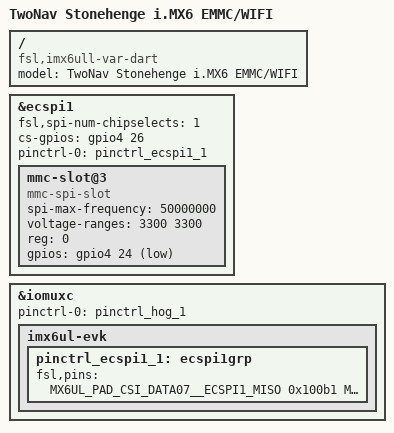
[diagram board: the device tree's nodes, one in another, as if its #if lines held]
/*
 * Copyright (C) 2015 Freescale Semiconductor, Inc.
 *
 * Copyright (C) 2015-2016 Variscite Ltd. - http://www.variscite.com
 *
 * This program is free software; you can redistribute it and/or modify
 * it under the terms of the GNU General Public License version 2 as
 * published by the Free Software Foundation.
 */
/* #define WIFI */
/* #define EMMC */
/* #define  NAND  */
/dts-v1/;

#include <dt-bindings/input/input.h>
#include "imx6ull.dtsi"
#include "imx6ul-imx6ull-var-dart-common.dtsi"

/ {
#ifdef NAND
#ifdef WIFI
	model = "Variscite i.MX6 ULL DART NAND/WIFI";
#else
	model = "Variscite i.MX6 ULL DART NAND/SD";
#endif
#endif
#ifdef EMMC
#ifdef WIFI
	model = "TwoNav Stonehenge i.MX6 EMMC/WIFI";
#else
	model = "Variscite i.MX6 ULL DART EMMC/SD";
#endif
#endif
	compatible = "fsl,imx6ull-var-dart", "fsl,imx6ull";
};

&ecspi1 {
	fsl,spi-num-chipselects = <1>;
	cs-gpios = <&gpio4 26 0>;
	pinctrl-names = "default";
	pinctrl-0 = <&pinctrl_ecspi1_1>;
	status = "okay";

	mmc-slot@3{
		compatible = "mmc-spi-slot";
        	spi-max-frequency = <50000000>;
		voltage-ranges = <3300 3300>;
		reg = <0>;
		gpios = <&gpio4 24 GPIO_ACTIVE_LOW>;
	};
};

&iomuxc {
	pinctrl-names = "default";
	pinctrl-0 = <&pinctrl_hog_1>;
	imx6ul-evk {

		pinctrl_ecspi1_1: ecspi1grp {
			fsl,pins = <
				MX6UL_PAD_CSI_DATA07__ECSPI1_MISO       0x100b1
				MX6UL_PAD_CSI_DATA06__ECSPI1_MOSI       0x100b1
				MX6UL_PAD_CSI_DATA04__ECSPI1_SCLK       0x100b1
				MX6UL_PAD_CSI_DATA05__GPIO4_IO26        0x100b1
				MX6UL_PAD_CSI_DATA03__GPIO4_IO24        0x100b1 /* CD_SPI_SD */
			>;
		};
	};
};

/*
&gpio1 {
	wlan_enable {
		gpio-hog;
        gpios = <29 GPIO_ACTIVE_HIGH>;
        output-low;
        line-name = "wlan_enable";
	};
	wlan_switch {
		gpio-hog;
        gpios = <31 GPIO_ACTIVE_HIGH>;
        output-low;
        line-name = "wlan_switch";
	};
};
*/
